# H6 register map
Vendor: Allwinner; Series: H6; File version: 0.1
CPU: CA53 0, little endian, MPU, no FPU, 0 interrupt priority bits
Registers are 32-bit, read-write, reset 0x0 unless marked. A register's access mark holds for its fields unless they carry their own. Offsets are from the block's base; [hi:lo] are bit positions.

## ATE_TV_Encoder
Base 0x00004000
0x00 TVE_CTL0 — TV Encoder Control 0 Register
  [0] EN — TV Encoder enable, default disable, write 1 to take it out of the reset state
0x02 TVE_CTL1 — TV Encoder Control 1 Register
  [15] CLK_DISABLE — TV Encoder clock gate disable 1: disable 0: enable
    1=disable; 0=enable
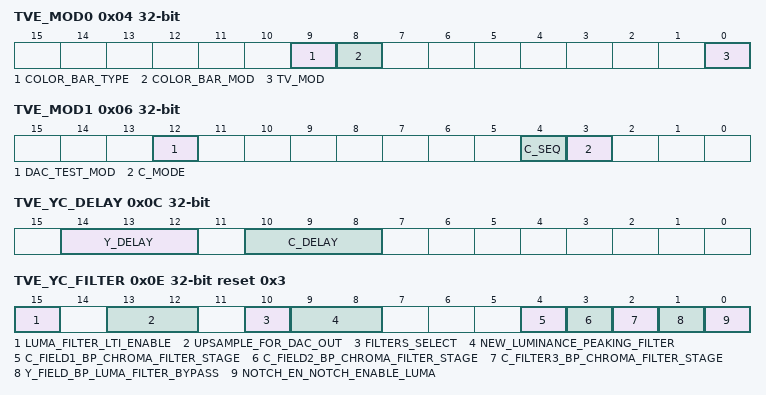
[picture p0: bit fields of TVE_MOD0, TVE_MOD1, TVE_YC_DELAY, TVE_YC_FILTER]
0x04 TVE_MOD0 — TV Encoder Mode 0 Register
  [9] COLOR_BAR_TYPE — Color Bar Type 0: NTSC: 75/7.5/75/7.5 PAL: 100/0/75/0 1: NTSC: 100/7.5/100/7.5 PAL: 100/0/100/0
    0=NTSC_colon__75_slash_7_point_5_slash_75_slash_7_point_5 (NTSC: 75/7.5/75/7.5 PAL: 100/0/75/0); 1=NTSC_colon__100_slash_7_point_5_slash_100_slash_7_point_5 (NTSC: 100/7.5/100/7.5 PAL: 100/0/100/0)
  [8] COLOR_BAR_MOD — Color Bar Mode Standard Color bar input selection This bit selects whether the Video Encoder video data input is replaced by an internal standard color bar generator or not. 0: The Video Encoder input is coming from the Display Engineer 1: The Video Encoder input is coming from an internal standard color bar generator.
    0=coming_from_the_Display (The Video Encoder input is coming from the Display Engineer); 1=coming_from_an (The Video Encoder input is coming from an internal standard color bar generator.)
  [0] TV_MOD — TV Mode Select 0: NTSC 1: PAL Changing this register value will cause some relative register setting to relative value.
    0=NTSC; 1=PAL (PAL Changing this register value will cause some relative register setting to relative value.)
0x06 TVE_MOD1 — TV Encoder Mode 1 Register
  [12] DAC_TEST_MOD — 0: TV mode, DAC using tvclk 1: DAC test mode DAC using AHB clock
    0=TV (TV mode, DAC using tvclk); 1=DAC (DAC test mode DAC using AHB clock)
  [4] C_SEQ — Cb/Cr sequence for 422 mode 0: Cb first 1: Cr first
    0=Cb (Cb first); 1=Cr (Cr first)
  [3] C_MODE — Chroma Mode 0: 444 1: 422
    0=_444; 1=_422
0x08 TVE_DAC_CFG0 — TV Encoder DAC Configuration 0 Register
  [0] DAC_EN — DAC Enable 0:disable 1:enable
0x0A TVE_DAC_CFG1 reset not defined — TV Encoder DAC Configuration 1 Register
0x0C TVE_YC_DELAY — TV Encoder YC Delay Register
  [14:12] Y_DELAY, [10:8] C_DELAY
0x0E TVE_YC_FILTER reset 0x3 — TV Encoder YC Filter Register
  [15] LUMA_FILTER_LTI_ENABLE — Luma filter lti enable 0:disable Luma filter lti 1:enable Luma filter lti
  [13:12] UPSAMPLE_FOR_DAC_OUT — upsample for dac Out up sample 0:27M 1:54M 2:108M 3:216M
  [10] FILTERS_SELECT — Filters_Select 0: enable new peaking filter 1: enable new reduction filter
    0=enable new peaking filter; 1=enable new reduction filter
  [9:8] NEW_LUMINANCE_PEAKING_FILTER — New luminance peaking filter selection
  [4] C_FIELD1_BP_CHROMA_FILTER_STAGE — C_FIELD1_BP Chroma Filter Stage 1 0 : Chroma Filter stage 1 Enable 1: Chroma Filter stage 1 bypass
    1=Chroma Filter stage 1 bypass
  [3] C_FIELD2_BP_CHROMA_FILTER_STAGE — C_FIELD2_BP Chroma Filter Stage 2 Bypass 0 : Chroma Filter stage 2 Enable 1: Chroma Filter stage 2 bypass
    1=Chroma Filter stage 2 bypass
  [2] C_FILTER3_BP_CHROMA_FILTER_STAGE — C_FILTER3_BP Chroma Filter Stage 3 Bypass 0 : Chroma Filter stage 3 Enable 1: Chroma Filter stage 3 bypass
    1=Chroma Filter stage 3 bypass
  [1] Y_FIELD_BP_LUMA_FILTER_BYPASS — Y_FIELD_BP Luma Filter Bypass 0: Luma Filter enable 1: Luma Filter bypass
    0=Luma_Filter_enable; 1=Luma Filter bypass
  [0] NOTCH_EN_NOTCH_ENABLE_LUMA — NOTCH_EN Notch Enable Luma notch filter on/off selection This bit selects if the luma notch filter is operating or bypassed. 0: The luma notch filter is bypassed 1: The luma notch filter is operating
    0=bypassed (The luma notch filter is bypassed); 1=operating (The luma notch filter is operating)
0x12 TVE_BURST_FRQ1 reset 0x21F0 — TV Encoder Burst Frequency 1 Register
  [15:0] BURST_FRQ_31_16 — Specify the ratio between the color burst frequency. 32 bit unsigned fraction. Default value is h21f07c1f, which is compatible with NTSC specs. 3.5795455MHz (X`21F07C1F`): NTSC-M, NTSC-J 4.43361875 MHz(X`2A098ACB`): PAL-B, D, G, H,I, N 3.582056 MHz (X`21F69446`):PAL-N(Argentina) 3.579611 MHz (X`21E6EFE3`): PAL-M
0x14 TVE_FRONT_PORCH reset 0x20 — TV Encoder Front Porch Register
  [11:0] FRONT_PORCH — Front Porch must be even specify the width of the front porch in encoder clock cycles. 6 bit unsigned even integer. Allowed range is 10 to 62. Default value is 32.
0x16 TVE_BACK_PORCH reset 0x76 — TV Encoder Back Porch Register
  [8:0] BACK_PORCH — Back Porch Specify the width of the back porch in encoder clock cycles. Min value is (burst_width+breeze_way+17). 8 bit unsigned integer. Default value is 118
0x1C TVE_TOTAL_LINE reset 0x20D — TV Encoder Total Line Number Register
  [10:0] NUM_LINES — Number Lines Specify the total number of lines in a video frame. 11 bit unsigned integer. Allowed range is 0 to 2048. Default value is 525. For interlaced video: When NTSC, and FirstVideoLine is greater than 20, then NumLines is restricted to be greater than 2*(FirstVideoLine+18). When NTSC, and FirstVideoLine is not greater than 20, then NumLines is restricted to be greater than 77. When PAL, and FirstVideoLine is greater than 22, then NumLines is restricted to be greater than 2*(FirstVideoLine+18). When PAL, and FirstVideoLine is not greater than 22, then NumLines is restricted to be greater than 81. If NumLines is even, then it is restricted to be divisible by 4. If NumLines is odd, then it is restricted to be divisible by 4 with a remainder of 1.
0x1E TVE_FIRST_ACTIVE reset 0x16 — TV Encoder First Active Line Register
  [7:0] FIRST_VIDEO_LINE — First Video Line Specify the index of the first line in a field/frame to have active video. 8 bit unsigned integer. For interlaced video: When VSync5=B`0`, FirstVideoLine is restricted to be greater than 7. When VSync5=B`1`, FirstVideoLine is restricted to be greater than 9. Default value is 21.
0x20 TVE_BLACK_LEVEL reset 0x11A — TV Encoder Black Level Register
  [9:0] BLACK_LEVEL — Black Level Specify the black level setting. 10 bit unsigned integer. Allowed range is 240 to 1023. Default value is 282
0x22 TVE_BLANK_LEVEL reset 0xF0 — TV Encoder Blank Level Register
  [9:0] BLANK_LEVEL — Blank Level Specify the blank level setting for active lines. 10 bit unsigned integer. Allowed range 0 to 1023. Default value is hexF0(dec240).
0x30 TVE_PLUG_EN — TV Encoder Plug Detect Enable Register
  [0] AUTO_DET_EN — Auto Detection Enable
0x32 TVE_PLUG_IRQ_EN — TV Encoder Plug Detect Interrupt Enable Register
  [0] AUTO_DET_IRQ_EN — Auto Detection Interrupt Enable
0x34 TVE_PLUG_IRQ_STA — TV Encoder Plug Detect Interrupt Status Register
  [0] AUTO_DET_IRQ_STA — Auto detection interrupt active flag, write 1 to inactive DAC0 auto detection interrupt.
0x38 TVE_PLUG_STA — TV Encoder Plug Detect Status Register
  [0] AUTO_DET_STA — DAC Status 00: Unconnected 01: Connected 11: Short to ground 10: Reserved
0x40 TVE_PLUG_DEBOUNCE — TV Encoder Plug Detect De-Bounce Register
  [3:0] DAC_DE_BNC — DAC debounce times
0xF4 TVE_PLUG_PULSE_LEVEL — TV Encoder Plug Detect Pulse Level Register
  [9:0] DETECT_PULSE_LEVEL — Use for DAC data input at auto detect pluse
0xF8 TVE_PLUG_PULSE_START — TV Encoder Plug Detect Pulse Start Register
  [14:0] DETECT_PULSE_START
0xFA TVE_PLUG_PULSE_PERIOD — TV Encoder Auto Detect Pulse Period Register
  [14:0] DETECT_PULSE_PERIOD — Use 32K clock
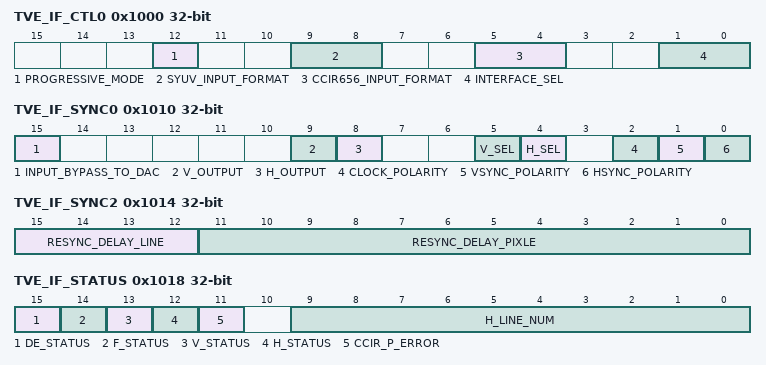
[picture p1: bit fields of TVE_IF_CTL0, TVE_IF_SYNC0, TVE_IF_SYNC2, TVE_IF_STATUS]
0x1000 TVE_IF_CTL0
  [12] PROGRESSIVE_MODE — 0: interlaced 1: progressive
    0=interlaced; 1=progressive
  [9:8] SYUV_INPUT_FORMAT — 000: YUV 001: YVU 010: UYV 011: UVY 100: VYU 101: VUY Others: reserved
  [5:4] CCIR656_INPUT_FORMAT — 00: YUYV 01: YVYU 10: UYVY 11: VYUY
    0=YUYV; 1=YVYU; 2=UYVY; 3=VYUY
  [1:0] INTERFACE_SEL — 0 : CCIR656 input interface 1 : Serial YUV input interface
0x1008 TVE_IF_TIM0 — TV Encoder Interface Timing 0 Register
  [8:0] HBP — horizontal back porch T = HBP×T
0x100A TVE_IF_TIM1 — TV Encoder Interface Timing 1 Register
  [11:0] HACT — Horizontal active cycle T = H_HACT×T
0x100C TVE_IF_TIM2 — TV Encoder Interface Timing 2 Register
  [8:0] VBP_ODD — Vertical back porch in line T = VBP×T
0x100E TVE_IF_TIM3 — TV Encoder Interface Timing 3 Register
  [9:0] VACT — Vertical active in line T = VACT×T
0x1010 TVE_IF_SYNC0 — TV Encoder Interface SYNC 0 Register
  [15] INPUT_BYPASS_TO_DAC — 0: normal 1: D[7:0] - DAC[7:0], HSYNC - DAC[8], VSYNC-DAC[9]
    0=normal; 1=D[7_colon_0] (D[7:0] - DAC[7:0], HSYNC - DAC[8], VSYNC-DAC[9])
  [9] V_OUTPUT — 0: VSYNC IO normal mode, as input 1: internal V signal output to VSYNC IO
    0=VSYNC (VSYNC IO normal mode, as input); 1=internal V signal output to VSYNC IO
  [8] H_OUTPUT — 0: HSYNC IO normal mode, as input 1: internal H signal output to HSYNC IO
    0=HSYNC (HSYNC IO normal mode, as input); 1=internal H signal output to HSYNC IO
  [5] V_SEL — 0 : internal V signal from sync CCIR reference codes 1 : internal V signal from sync IO generator Node that internal DE signal is generate from internal V and H signal
  [4] H_SEL — 0 : internal H signal from sync CCIR reference codes 1 : internal H signal from sync IO generator that internal DE signal is generated from internal V and H signal
  [2] CLOCK_POLARITY — 0: latch data from clock falling edge 1: latch data from clock rising edge
    0=latch_data_from_clock_falling_edge; 1=latch_data_from_clock_rising_edge
  [1] VSYNC_POLARITY — 0: active 0 1: active 1
    0=active_0; 1=active_1
  [0] HSYNC_POLARITY — 0: active 0 1: active 1
    0=active_0; 1=active_1
0x1012 TVE_IF_SYNC1 — TV Encoder Interface SYNC 1 Register
  [2:0] RESYNC_INTERVAL_TIME — 000 : Disable 001 : once at start 010 : every 4 vsync 011 : every 8 vsync 100 : every 16 vsync Others : Disable
0x1014 TVE_IF_SYNC2 — TV Encoder Interface SYNC 2 Register
  [15:12] RESYNC_DELAY_LINE
  [11:0] RESYNC_DELAY_PIXLE — Count by dclk
0x1016 TVE_IF_TIM4 — TV Encoder Interface Timing 4 Register
  [8:0] VBP_EVEN — Vertical back porch in line T = VBP×T
0x1018 TVE_IF_STATUS — TV Encoder Interface Status Register
  [15] DE_STATUS ro — Internal DE signal status
  [14] F_STATUS ro — Internal F signal status
  [13] V_STATUS ro — Internal V signal status
  [12] H_STATUS ro — Internal H signal status
  [11] CCIR_P_ERROR ro — If CCIR code P3-P0 is not equal to H V F XOR result, this bit is set`1`, write `1` to clear this bit.
  [9:0] H_LINE_NUM ro — Indecate total H signal cycle number in a Frame time.
